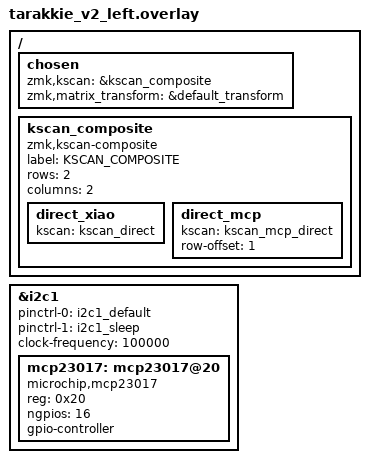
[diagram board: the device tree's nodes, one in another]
#include <dt-bindings/zmk/matrix_transform.h>
#include <dt-bindings/zmk/keys.h>
#include <dt-bindings/zmk/mouse.h>
#include <dt-bindings/gpio/gpio.h>
#include <dt-bindings/i2c/i2c.h>
#include "tarakkie_v2.dtsi"
#include "pinctrl.dtsi"
#include "module_1.dtsi"

/ {
    chosen {
        zmk,kscan = &kscan_composite;
        zmk,matrix_transform = &default_transform;
    };

    kscan_composite: kscan_composite {
        compatible = "zmk,kscan-composite";
        label = "KSCAN_COMPOSITE";
        rows = <2>;
        columns = <2>;

        direct_xiao {
            kscan = <&kscan_direct>;
        };

        direct_mcp {
            kscan = <&kscan_mcp_direct>;
            row-offset = <1>;
        };
    };
};

&i2c1 {
    status = "okay";
    pinctrl-0 = <&i2c1_default>;
    pinctrl-1 = <&i2c1_sleep>;
    pinctrl-names = "default", "sleep";
    clock-frequency = <100000>;

    mcp23017: mcp23017@20 {
        compatible = "microchip,mcp23017";
        status = "okay";
        reg = <0x20>;
        ngpios = <16>;
        gpio-controller;
        #gpio-cells = <2>;
    };
};
